# STM32WBA24 register map
File version: 0.2
CPU: CM33 r0p1, little endian, MPU, FPU, 4 interrupt priority bits
Registers are 32-bit, read-write, reset 0x0 unless marked. A register's access mark holds for its fields unless they carry their own. Offsets are from the block's base; [hi:lo] are bit positions; 'fields as' and 'values as' point back to an identical list.

## GTZC1_TZSC — GTZC1_TZSC address block description
Base 0x40032400
Same registers: SEC_GTZC1_TZSC 0x50032400
0x00 GTZC1_TZSC_CR — GTZC1 TZSC control register
  [0] LCK — Lock the configuration of GTZC1_TZSC_SECCFGRn and GTZC1_TZSC_PRIVCFGRn registers until next reset
    0=Configuration of all GTZC1_TZSC_SECCFGRn and GTZC1_TZSC_PRIVCFGRn registers not locked; 1=Configuration of all GTZC1_TZSC_SECCFGRn and GTZC1_TZSC_PRIVCFGRn registers locked
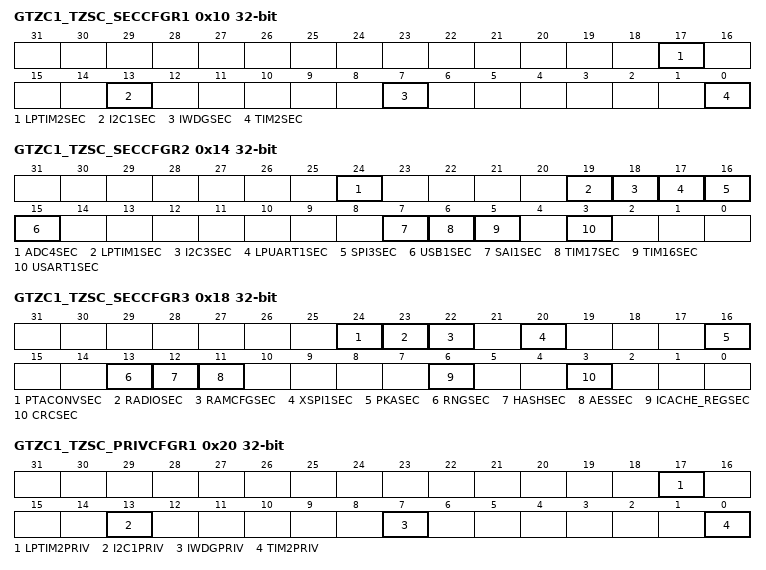
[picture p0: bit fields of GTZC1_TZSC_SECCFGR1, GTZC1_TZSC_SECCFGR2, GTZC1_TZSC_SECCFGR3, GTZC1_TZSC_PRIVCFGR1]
0x10 GTZC1_TZSC_SECCFGR1 — GTZC1 TZSC secure configuration register 1
  [all] fields
    0=Nonsecure; 1=Secure
  [17] LPTIM2SEC — Secure access mode for LPTIM2
  [13] I2C1SEC — Secure access mode for I2C1
  [7] IWDGSEC — Secure access mode for IWDG
  [0] TIM2SEC — Secure access mode for TIM2
0x14 GTZC1_TZSC_SECCFGR2 — GTZC1 TZSC secure configuration register 2
  [24] ADC4SEC — Secure access mode for ADC4
    0=Nonsecure; 1=Secure
  [19] LPTIM1SEC — Secure access mode for LPTIM1
    0=Nonsecure; 1=Secure
  [18] I2C3SEC — Secure access mode for I2C3
    0=Nonsecure; 1=Secure
  [17] LPUART1SEC — Secure access mode for LPUART1
    0=Nonsecure; 1=Secure
  [16] SPI3SEC — Secure access mode for SPI3
    0=Nonsecure; 1=Secure
  [15] USB1SEC
  [7] SAI1SEC — Secure access mode for SAI1
    0=Nonsecure; 1=Secure
  [6] TIM17SEC — Secure access mode for TIM17
    0=Nonsecure; 1=Secure
  [5] TIM16SEC — Secure access mode for TIM16
    0=Nonsecure; 1=Secure
  [3] USART1SEC — Secure access mode for USART1
    0=Nonsecure; 1=Secure
0x18 GTZC1_TZSC_SECCFGR3 — GTZC1 TZSC secure configuration register 3
  [all] fields
    0=Nonsecure; 1=Secure
  [24] PTACONVSEC — Secure access mode for PTACONV
  [23] RADIOSEC — Secure access mode for 2.
  [22] RAMCFGSEC — Secure access mode for RAMCFG
  [20] XSPI1SEC — Secure access mode for XSPI1
  [16] PKASEC — Secure access mode for PKA
  [13] RNGSEC — Secure access mode for RNG
  [12] HASHSEC — Secure access mode for HASH
  [11] AESSEC — Secure access mode for AES
  [6] ICACHE_REGSEC — Secure access mode for ICACHE registers
  [3] CRCSEC — Secure access mode for CRC
0x20 GTZC1_TZSC_PRIVCFGR1 — GTZC1 TZSC privilege configuration register 1
  [all] fields
    0=Unprivileged; 1=Privileged
  [17] LPTIM2PRIV — Privileged access mode for LPTIM2
  [13] I2C1PRIV — Privileged access mode for I2C1
  [7] IWDGPRIV — Privileged access mode for IWDG
  [0] TIM2PRIV — Privileged access mode for TIM2
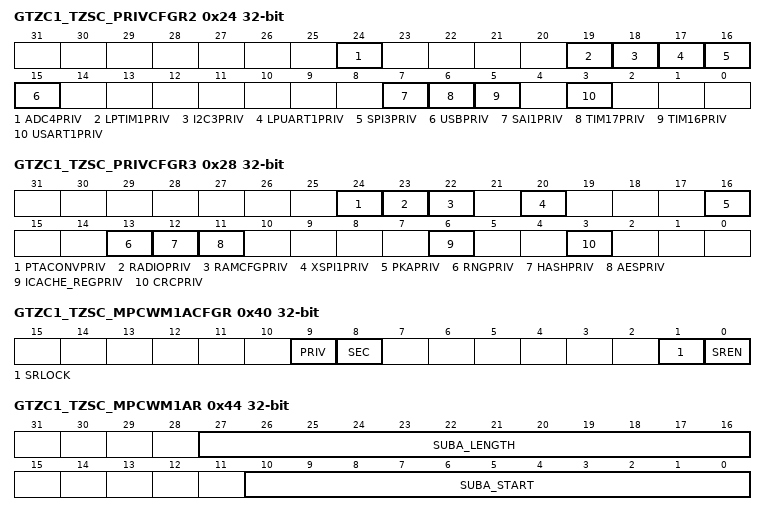
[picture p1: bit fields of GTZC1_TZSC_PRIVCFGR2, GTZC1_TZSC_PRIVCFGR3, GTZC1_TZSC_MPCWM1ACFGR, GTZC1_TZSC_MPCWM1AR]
0x24 GTZC1_TZSC_PRIVCFGR2 — GTZC1 TZSC privilege configuration register 2
  [all] fields
    0=Unprivileged; 1=Privileged
  [24] ADC4PRIV — Privileged access mode for ADC4
  [19] LPTIM1PRIV — Privileged access mode for LPTIM1
  [18] I2C3PRIV — Privileged access mode for I2C3
  [17] LPUART1PRIV — Privileged access mode for LPUART1
  [16] SPI3PRIV — Privileged access mode for SPI3
  [15] USBPRIV — Privileged access mode for USB
  [7] SAI1PRIV — Privileged access mode for SAI1
  [6] TIM17PRIV — Privileged access mode for TIM17
  [5] TIM16PRIV — Privileged access mode for TIM16
  [3] USART1PRIV — Privileged access mode for USART1
0x28 GTZC1_TZSC_PRIVCFGR3 — GTZC1 TZSC privilege configuration register 3
  [all] fields
    0=Unprivileged; 1=Privileged
  [24] PTACONVPRIV — Privileged access mode for PTACONV
  [23] RADIOPRIV — Privileged access mode for 2.
  [22] RAMCFGPRIV — Privileged access mode for RAMCFG
  [20] XSPI1PRIV — Privileged access mode for XSPI1
  [16] PKAPRIV — Privileged access mode for PKA
  [13] RNGPRIV — Privileged access mode for RNG
  [12] HASHPRIV — Privileged access mode for HASH
  [11] AESPRIV — Privileged access mode for AES
  [6] ICACHE_REGPRIV — Privileged access mode for ICACHE registers
  [3] CRCPRIV — Privileged access mode for CRC
0x40 GTZC1_TZSC_MPCWM1ACFGR — GTZC1 TZSC memory 1 sub-region A watermark configuration register
  [9] PRIV — Privileged sub-region z
    0=Privileged and unprivileged accesses are granted in sub-region z; 1=Only privileged accesses are granted in sub-region z
  [8] SEC — Secure sub-region z
    0=Only nonsecure data accesses are granted to sub-region z; 1=Only secure data accesses are granted to sub-region z
  [1] SRLOCK — Sub-region z lock
    0=GTZC1_TZSC_MPCWM1zCFGR, GTZC1_TZSC_MPCWM1zR can be written; 1=Writes to GTZC1_TZSC_MPCWM1zCFGR, GTZC1_TZSC_MPCWM1zR are ignored
  [0] SREN — Sub-region z enable
    0=Sub-region z is disabled; 1=Sub-region z is enabled
0x44 GTZC1_TZSC_MPCWM1AR — GTZC1 TZSC memory 1 sub-region A watermark register
  [27:16] SUBA_LENGTH — Length of sub-region A
  [10:0] SUBA_START — Start of sub-region A
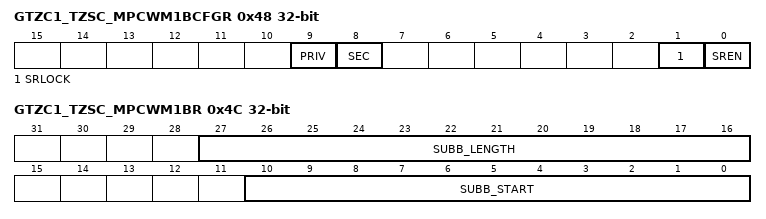
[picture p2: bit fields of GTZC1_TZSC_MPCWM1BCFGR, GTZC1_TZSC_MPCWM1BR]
0x48 GTZC1_TZSC_MPCWM1BCFGR — GTZC1 TZSC memory 1 sub-region B watermark configuration register
  fields as GTZC1_TZSC_MPCWM1ACFGR
0x4C GTZC1_TZSC_MPCWM1BR — GTZC1 TZSC memory 1 sub-region B watermark register
  [27:16] SUBB_LENGTH — Length of sub-region B
  [10:0] SUBB_START — Start of sub-region B
